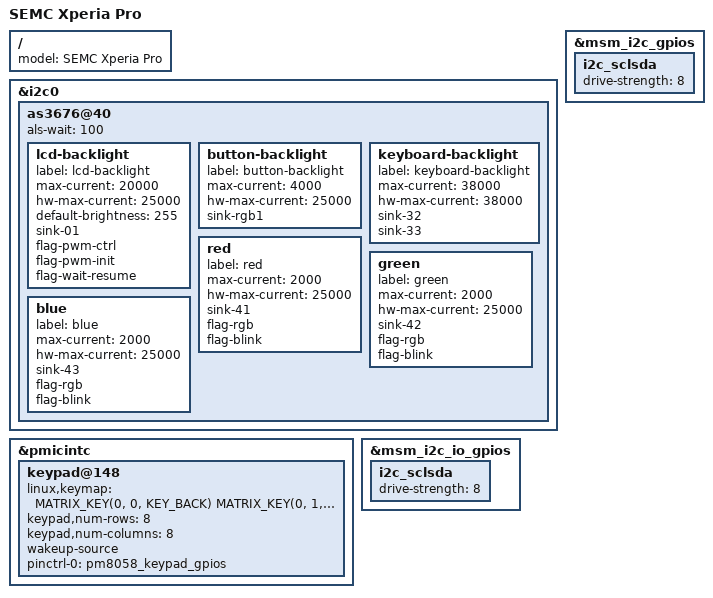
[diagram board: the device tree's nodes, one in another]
#include "qcom-msm7x30-semc-mogami.dtsi"

#include <dt-bindings/input/input.h>

/ {
	model = "SEMC Xperia Pro";
};

&i2c0 {
	as3676@40 {
		als-wait = <100>;

		lcd-backlight {
			label = "lcd-backlight";
			max-current = <20000>;
			hw-max-current = <25000>;
			default-brightness = <255>;
			sink-01;
			flag-pwm-ctrl;
			flag-pwm-init;
			flag-wait-resume;
		};

		button-backlight {
			label = "button-backlight";
			max-current = <4000>;
			hw-max-current = <25000>;
			sink-rgb1;
		};

		keyboard-backlight {
			label = "keyboard-backlight";
			max-current = <38000>;
			hw-max-current = <38000>;
			sink-32;
			sink-33;
		};

		red {
			label = "red";
			max-current = <2000>;
			hw-max-current = <25000>;
			sink-41;
			flag-rgb;
			flag-blink;
		};

		green {
			label = "green";
			max-current = <2000>;
			hw-max-current = <25000>;
			sink-42;
			flag-rgb;
			flag-blink;
		};

		blue {
			label = "blue";
			max-current = <2000>;
			hw-max-current = <25000>;
			sink-43;
			flag-rgb;
			flag-blink;
		};
	};
};

&pmicintc {
	keypad@148 {
		linux,keymap = <
			MATRIX_KEY(0, 0, KEY_BACK)
			MATRIX_KEY(0, 1, KEY_HOME)
			MATRIX_KEY(0, 2, KEY_MENU)
			MATRIX_KEY(0, 3, KEY_LEFTSHIFT)
			MATRIX_KEY(0, 7, KEY_W)

			MATRIX_KEY(1, 0, KEY_CAMERA_FOCUS)
			MATRIX_KEY(1, 1, KEY_CAMERA)
			MATRIX_KEY(1, 2, KEY_VOLUMEDOWN)
			MATRIX_KEY(1, 3, KEY_VOLUMEUP)
			MATRIX_KEY(1, 4, KEY_Q)
			MATRIX_KEY(1, 5, KEY_G)
			MATRIX_KEY(1, 6, KEY_U)
			MATRIX_KEY(1, 7, KEY_S)

			MATRIX_KEY(2, 0, KEY_LANGUAGE)
			MATRIX_KEY(2, 3, KEY_F)
			MATRIX_KEY(2, 5, KEY_LEFTBRACE)
			MATRIX_KEY(2, 6, KEY_N)
			MATRIX_KEY(2, 7, KEY_O)

			MATRIX_KEY(3, 0, KEY_SPACE)
			MATRIX_KEY(3, 1, KEY_A)
			MATRIX_KEY(3, 2, KEY_B)
			MATRIX_KEY(3, 3, KEY_RIGHTBRACE)
			MATRIX_KEY(3, 4, KEY_R)
			MATRIX_KEY(3, 6, KEY_J)

			MATRIX_KEY(4, 0, KEY_ENTER)
			MATRIX_KEY(4, 1, KEY_D)
			MATRIX_KEY(4, 3, KEY_Z)
			MATRIX_KEY(4, 4, KEY_C)
			MATRIX_KEY(4, 5, KEY_Y)
			MATRIX_KEY(4, 7, KEY_L)

			MATRIX_KEY(5, 0, KEY_DOT)
			MATRIX_KEY(5, 1, KEY_APOSTROPHE)
			MATRIX_KEY(5, 2, KEY_COMMA)
			MATRIX_KEY(5, 3, KEY_E)
			MATRIX_KEY(5, 4, KEY_T)
			MATRIX_KEY(5, 5, KEY_H)
			MATRIX_KEY(5, 6, KEY_I)

			MATRIX_KEY(6, 0, KEY_UP)
			MATRIX_KEY(6, 1, KEY_DOWN)
			MATRIX_KEY(6, 4, KEY_LEFTALT)
			MATRIX_KEY(6, 5, KEY_COMPOSE)
			MATRIX_KEY(6, 6, KEY_K)
			MATRIX_KEY(6, 7, KEY_BACKSPACE)

			MATRIX_KEY(7, 2, KEY_RIGHT)
			MATRIX_KEY(7, 3, KEY_LEFT)
			MATRIX_KEY(7, 4, KEY_V)
			MATRIX_KEY(7, 5, KEY_X)
			MATRIX_KEY(7, 6, KEY_M)
			MATRIX_KEY(7, 7, KEY_P)
			>;
		keypad,num-rows = <8>;
		keypad,num-columns = <8>;
		wakeup-source;

		pinctrl-names = "default";
		pinctrl-0 = <&pm8058_keypad_gpios>;
	};
};

&msm_i2c_gpios {
	i2c_sclsda {
		drive-strength = <8>;
	};
};

&msm_i2c_io_gpios {
	i2c_sclsda {
		drive-strength = <8>;
	};
};
